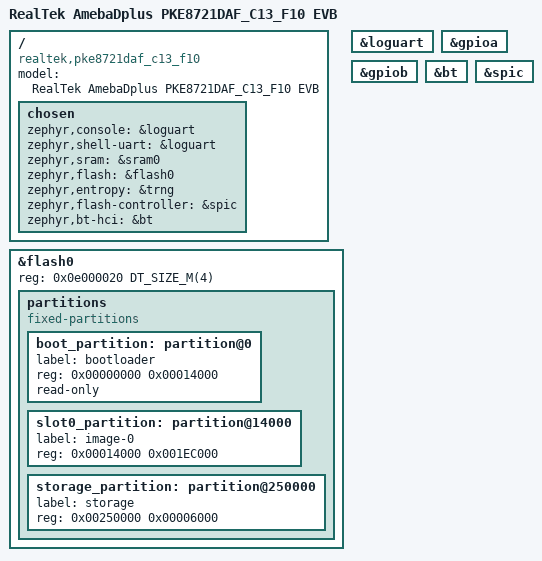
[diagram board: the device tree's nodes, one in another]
/*
 * Copyright (c) 2026 Realtek Semiconductor Corp.
 *
 * SPDX-License-Identifier: Apache-2.0
 */

/dts-v1/;

#include <realtek/amebadplus/amebadplus.dtsi>
#include "pke8721daf_c13_f10-pinctrl.dtsi"

/ {
	model = "RealTek AmebaDplus PKE8721DAF_C13_F10 EVB";
	compatible = "realtek,pke8721daf_c13_f10";

	chosen {
		zephyr,console = &loguart;
		zephyr,shell-uart = &loguart;
		zephyr,sram = &sram0;
		zephyr,flash = &flash0;
		zephyr,entropy = &trng;
		zephyr,flash-controller = &spic;
		zephyr,bt-hci = &bt;
	};
};

/* 4MB flash */
&flash0 {
	reg = <0x0e000020 DT_SIZE_M(4)>;

	partitions {
		compatible = "fixed-partitions";
		#address-cells = <1>;
		#size-cells = <1>;

		/* Reserve 80kB for the bootloader */
		boot_partition: partition@0 {
			label = "bootloader";
			reg = <0x00000000 0x00014000>;
			read-only;
		};

		/* Reserve 1968kB for the application in slot 0 */
		slot0_partition: partition@14000 {
			label = "image-0";
			reg = <0x00014000 0x001EC000>;
		};

		storage_partition: partition@250000 {
			label = "storage";
			reg = <0x00250000 0x00006000>;
		};
	};
};

&loguart {
	status = "okay";
};

&gpioa {
	status = "okay";
};

&gpiob {
	status = "okay";
};

&bt {
	status = "okay";
};

&spic {
	status = "okay";
};
